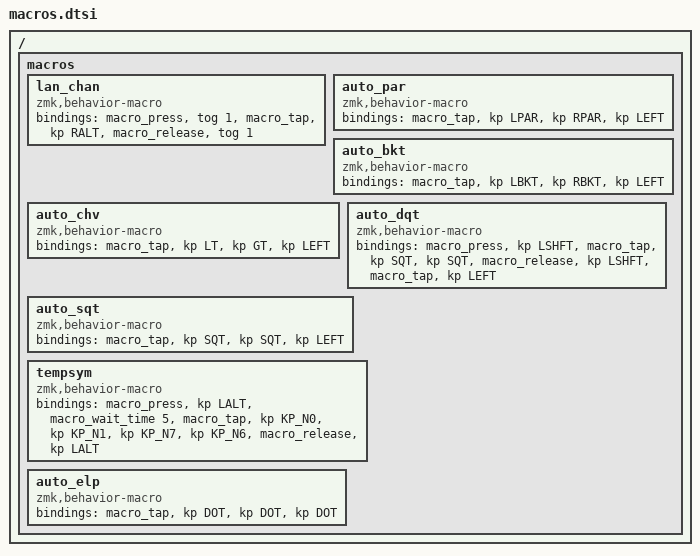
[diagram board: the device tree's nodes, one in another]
/ {
    macros {

// start of macro list

// language change and layer change at the same time
        lan_chan: lan_chan {
            compatible = "zmk,behavior-macro";
            #binding-cells = <0>;
            bindings 
                = <&macro_press &tog 1>
                , <&macro_tap &kp RALT>
                , <&macro_release &tog 1>
                ;
        };

// automatically write two parentheses
        auto_par: auto_par {
            compatible = "zmk,behavior-macro";
            #binding-cells = <0>;
            bindings
                = <&macro_tap &kp LPAR &kp RPAR &kp LEFT>
                ;
        };

// automatically write two brackets
        auto_bkt: auto_bkt {
            compatible = "zmk,behavior-macro";
            #binding-cells = <0>;
            bindings
                = <&macro_tap &kp LBKT &kp RBKT &kp LEFT>
                ;
        };

// automatically write two chevrons
        auto_chv: auto_chv {
            compatible = "zmk,behavior-macro";
            #binding-cells = <0>;
            bindings
                = <&macro_tap &kp LT &kp GT &kp LEFT>
                ;
        };

// automatically write two quotations
        auto_dqt: auto_dqt {
            compatible = "zmk,behavior-macro";
            #binding-cells = <0>;
            bindings
                = <&macro_press &kp LSHFT>
                , <&macro_tap &kp SQT &kp SQT>
                , <&macro_release &kp LSHFT>
                , <&macro_tap &kp LEFT>

                ;
        };

// automatically write two small quotations
        auto_sqt: auto_sqt {
            compatible = "zmk,behavior-macro";
            #binding-cells = <0>;
            bindings
                = <&macro_tap &kp SQT &kp SQT &kp LEFT>
                ;
        };

// automatically write temperature symbol
        tempsym: tempsym {
            compatible = "zmk,behavior-macro";
            #binding-cells = <0>;
            bindings
                = <&macro_press &kp LALT>
                , <&macro_wait_time 5>
                , <&macro_tap &kp KP_N0 &kp KP_N1 &kp KP_N7 &kp KP_N6>
                , <&macro_release &kp LALT>

                ;
        };

// automatically write three periods
        auto_elp: auto_elp {
            compatible = "zmk,behavior-macro";
            #binding-cells = <0>;
            bindings
                = <&macro_tap &kp DOT &kp DOT &kp DOT>
                ;
        };

// end of macro list

    };
};
